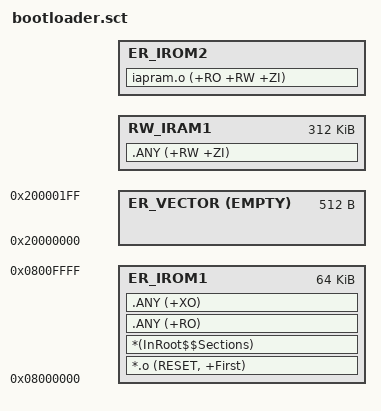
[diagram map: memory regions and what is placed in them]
; *************************************************************
; *** Scatter-Loading Description File generated by uVision ***
; *************************************************************

LR_IROM1 0x08000000 0x00010000  {    ; load region size_region
  ER_IROM1 0x08000000 0x00010000  {  ; load address = execution address
   *.o (RESET, +First)
   *(InRoot$$Sections)
   .ANY (+RO)
   .ANY (+XO)
  }
  ER_VECTOR 0x20000000 EMPTY 0x200 {
    ; empty
  }
  RW_IRAM1 +0 0x00004e000  {  ; RW data
   .ANY (+RW +ZI)
  }
  ; assign iapram.o running in the followed space in ram
  ER_IROM2 +0  {
   iapram.o (+RO +RW +ZI)
  }
  
}

